AUTOSAR XML (schema 00044)
package /E40_Platform_System_SystemPackage/Components
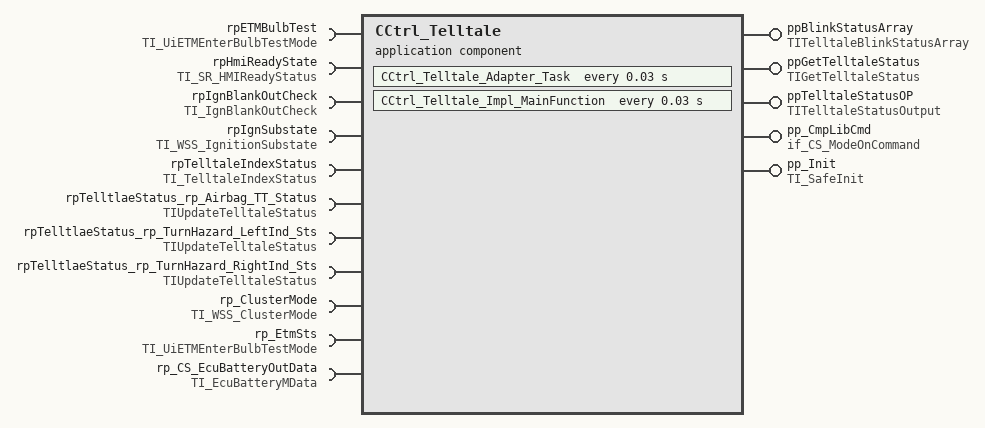
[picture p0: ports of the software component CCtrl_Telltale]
  application sw component type CCtrl_Telltale
    5 x provide port:
      ppBlinkStatusArray: provided-interface=TITelltaleBlinkStatusArray
        provided-com-specs:
          data-element=TTBlinkStatusArray, init-value=constant-reference=CCtrl_TelltaleTTBlinkStatusArrayValue0
          data-element=TTdummyDataForTypes, init-value=constant-reference=CCtrl_TelltaleTTdummyDataForTypesValue0
      ppGetTelltaleStatus: nonqueued-sender-com-spec{data-element=TelltaleFunctionalOpStatus, init-value=constant-reference=CCtrl_TelltaleTelltaleFunctionalOpStatusValue0}, provided-interface=TIGetTelltaleStatus
      ppTelltaleStatusOP: nonqueued-sender-com-spec{data-element=TelltaleOpArray, init-value=constant-reference=CCtrl_TelltaleTelltaleOpArrayValue0}, provided-interface=TITelltaleStatusOutput
      pp_CmpLibCmd: server-com-spec{operation=Impl_OnCommand, queue-length=1}, provided-interface=if_CS_ModeOnCommand
      pp_Init: server-com-spec{operation=Init, queue-length=1}, provided-interface=TI_SafeInit
    11 x require port:
      rpETMBulbTest: nonqueued-receiver-com-spec{data-element=CurrentBulbTestStatus, init-value=constant-reference=CCtrl_TelltaleCurrentBulbTestStatusValue0}, required-interface=TI_UiETMEnterBulbTestMode
      rpHmiReadyState: nonqueued-receiver-com-spec{data-element=HMI_ReadyStatus, init-value=constant-reference=CCtrl_TelltaleHMI_ReadyStatusValue0}, required-interface=TI_SR_HMIReadyStatus
      rpIgnBlankOutCheck: nonqueued-receiver-com-spec{data-element=IgnBlankOutCheck, init-value=constant-reference=CCtrl_TelltaleIgnBlankOutCheckValue0}, required-interface=TI_IgnBlankOutCheck
      rpIgnSubstate: nonqueued-receiver-com-spec{data-element=IgnitionSubstate, init-value=constant-reference=CCtrl_TelltaleIgnitionSubstateValue0}, required-interface=TI_WSS_IgnitionSubstate
      rpTelltaleIndexStatus: required-interface=TI_TelltaleIndexStatus
        required-com-specs:
          data-element=TTIndex, init-value=constant-reference=CCtrl_TelltaleTTIndexValue0
          data-element=TTStatus, init-value=constant-reference=CCtrl_TelltaleTTStatusValue0
      rpTelltlaeStatus_rp_Airbag_TT_Status: nonqueued-receiver-com-spec{data-element=CurrentTelltaleStatus, init-value=constant-reference=CCtrl_TelltaleCurrentTelltaleStatusValue0}, required-interface=TIUpdateTelltaleStatus
      rpTelltlaeStatus_rp_TurnHazard_LeftInd_Sts: nonqueued-receiver-com-spec{data-element=CurrentTelltaleStatus, init-value=constant-reference=CCtrl_TelltaleCurrentTelltaleStatusValue0}, required-interface=TIUpdateTelltaleStatus
      rpTelltlaeStatus_rp_TurnHazard_RightInd_Sts: nonqueued-receiver-com-spec{data-element=CurrentTelltaleStatus, init-value=constant-reference=CCtrl_TelltaleCurrentTelltaleStatusValue0}, required-interface=TIUpdateTelltaleStatus
      rp_ClusterMode: nonqueued-receiver-com-spec{data-element=WSSCurrentClusterMode, init-value=constant-reference=CCtrl_TelltaleWSSCurrentClusterModeValue0}, required-interface=TI_WSS_ClusterMode
      rp_EtmSts: nonqueued-receiver-com-spec{data-element=CurrentBulbTestStatus, init-value=constant-reference=CCtrl_TelltaleCurrentBulbTestStatusValue0}, required-interface=TI_UiETMEnterBulbTestMode
      rp_CS_EcuBatteryOutData: required-com-specs=[EcuBatteryM_GetChannelStatus, EcuBatteryM_GetDIOStatus], required-interface=TI_EcuBatteryMData
    behavior IB_CCtrl_Telltale
      timing event TECCtrl_Telltale_Adapter_Task: start-on-event=CCtrl_Telltale_Adapter_Task, period=0.03
      timing event TECCtrl_Telltale_Impl_MainFunction: start-on-event=CCtrl_Telltale_Impl_MainFunction, period=0.03
      operation invoked event OIE_pp_CmpLibCmd_CCtrl_Telltale_Impl_OnCommandTrigByImpl_OnCommand: start-on-event=CCtrl_Telltale_Impl_OnCommand, operation=pp_CmpLibCmd.Impl_OnCommand
      operation invoked event OIE_pp_Init_CCtrl_Telltale_InitTrigByInit: start-on-event=CCtrl_Telltale_Init, operation=pp_Init.Init
      port-api-options:
        enable-take-address=false, indirect-api=false, port=ppBlinkStatusArray
        enable-take-address=false, indirect-api=false, port=ppGetTelltaleStatus
        enable-take-address=false, indirect-api=false, port=ppTelltaleStatusOP
        enable-take-address=false, indirect-api=false, port=pp_CmpLibCmd
        enable-take-address=false, indirect-api=false, port=pp_Init
        enable-take-address=false, indirect-api=false, port=rpETMBulbTest
        enable-take-address=false, indirect-api=false, port=rpHmiReadyState
        enable-take-address=false, indirect-api=false, port=rpIgnBlankOutCheck
        enable-take-address=false, indirect-api=false, port=rpIgnSubstate
        enable-take-address=false, indirect-api=false, port=rpTelltaleIndexStatus
        enable-take-address=false, indirect-api=false, port=rpTelltlaeStatus_rp_Airbag_TT_Status
        enable-take-address=false, indirect-api=false, port=rpTelltlaeStatus_rp_TurnHazard_LeftInd_Sts
        enable-take-address=false, indirect-api=false, port=rpTelltlaeStatus_rp_TurnHazard_RightInd_Sts
        enable-take-address=false, indirect-api=false, port=rp_ClusterMode
        enable-take-address=false, indirect-api=false, port=rp_EtmSts
        enable-take-address=false, indirect-api=false, port=rp_CS_EcuBatteryOutData
      4 x runnable, all with can-be-invoked-concurrently=true:
        CCtrl_Telltale_Adapter_Task
          data-receive-point-by-arguments:
            11 x access:
              DRA_rpETMBulbTest_CurrentBulbTestStatus: accessed-variable=rpETMBulbTest.CurrentBulbTestStatus
              DRA_rpHmiReadyState_HMI_ReadyStatus: accessed-variable=rpHmiReadyState.HMI_ReadyStatus
              DRA_rpIgnBlankOutCheck_IgnBlankOutCheck: accessed-variable=rpIgnBlankOutCheck.IgnBlankOutCheck
              DRA_rpIgnSubstate_IgnitionSubstate: accessed-variable=rpIgnSubstate.IgnitionSubstate
              DRA_rpTelltaleIndexStatus_TTIndex: accessed-variable=rpTelltaleIndexStatus.TTIndex
              DRA_rpTelltaleIndexStatus_TTStatus: accessed-variable=rpTelltaleIndexStatus.TTStatus
              DRA_rpTelltlaeStatus_rp_Airbag_TT_Status_CurrentTelltaleStatus: accessed-variable=rpTelltlaeStatus_rp_Airbag_TT_Status.CurrentTelltaleStatus
              DRA_rpTelltlaeStatus_rp_TurnHazard_LeftInd_Sts_CurrentTelltaleStatus: accessed-variable=rpTelltlaeStatus_rp_TurnHazard_LeftInd_Sts.CurrentTelltaleStatus
              DRA_rpTelltlaeStatus_rp_TurnHazard_RightInd_Sts_CurrentTelltaleStatus: accessed-variable=rpTelltlaeStatus_rp_TurnHazard_RightInd_Sts.CurrentTelltaleStatus
              DRA_rp_ClusterMode_WSSCurrentClusterMode: accessed-variable=rp_ClusterMode.WSSCurrentClusterMode
              DRA_rp_EtmSts_CurrentBulbTestStatus: accessed-variable=rp_EtmSts.CurrentBulbTestStatus
          data-send-points:
            4 x access:
              DWA_ppBlinkStatusArray_TTBlinkStatusArray: accessed-variable=ppBlinkStatusArray.TTBlinkStatusArray
              DWA_ppBlinkStatusArray_TTdummyDataForTypes: accessed-variable=ppBlinkStatusArray.TTdummyDataForTypes
              DWA_ppGetTelltaleStatus_TelltaleFunctionalOpStatus: accessed-variable=ppGetTelltaleStatus.TelltaleFunctionalOpStatus
              DWA_ppTelltaleStatusOP_TelltaleOpArray: accessed-variable=ppTelltaleStatusOP.TelltaleOpArray
          sync call OA_rp_CS_EcuBatteryOutData_EcuBatteryM_GetChannelStatus: operation=rp_CS_EcuBatteryOutData.EcuBatteryM_GetChannelStatus
          sync call OA_rp_CS_EcuBatteryOutData_EcuBatteryM_GetDIOStatus: operation=rp_CS_EcuBatteryOutData.EcuBatteryM_GetDIOStatus
        CCtrl_Telltale_Impl_MainFunction
          data-receive-point-by-arguments:
            11 x access:
              DRA_rpETMBulbTest_CurrentBulbTestStatus: accessed-variable=rpETMBulbTest.CurrentBulbTestStatus
              DRA_rpHmiReadyState_HMI_ReadyStatus: accessed-variable=rpHmiReadyState.HMI_ReadyStatus
              DRA_rpIgnBlankOutCheck_IgnBlankOutCheck: accessed-variable=rpIgnBlankOutCheck.IgnBlankOutCheck
              DRA_rpIgnSubstate_IgnitionSubstate: accessed-variable=rpIgnSubstate.IgnitionSubstate
              DRA_rpTelltaleIndexStatus_TTIndex: accessed-variable=rpTelltaleIndexStatus.TTIndex
              DRA_rpTelltaleIndexStatus_TTStatus: accessed-variable=rpTelltaleIndexStatus.TTStatus
              DRA_rpTelltlaeStatus_rp_Airbag_TT_Status_CurrentTelltaleStatus: accessed-variable=rpTelltlaeStatus_rp_Airbag_TT_Status.CurrentTelltaleStatus
              DRA_rpTelltlaeStatus_rp_TurnHazard_LeftInd_Sts_CurrentTelltaleStatus: accessed-variable=rpTelltlaeStatus_rp_TurnHazard_LeftInd_Sts.CurrentTelltaleStatus
              DRA_rpTelltlaeStatus_rp_TurnHazard_RightInd_Sts_CurrentTelltaleStatus: accessed-variable=rpTelltlaeStatus_rp_TurnHazard_RightInd_Sts.CurrentTelltaleStatus
              DRA_rp_ClusterMode_WSSCurrentClusterMode: accessed-variable=rp_ClusterMode.WSSCurrentClusterMode
              DRA_rp_EtmSts_CurrentBulbTestStatus: accessed-variable=rp_EtmSts.CurrentBulbTestStatus
          data-send-points:
            4 x access:
              DWA_ppBlinkStatusArray_TTBlinkStatusArray: accessed-variable=ppBlinkStatusArray.TTBlinkStatusArray
              DWA_ppBlinkStatusArray_TTdummyDataForTypes: accessed-variable=ppBlinkStatusArray.TTdummyDataForTypes
              DWA_ppGetTelltaleStatus_TelltaleFunctionalOpStatus: accessed-variable=ppGetTelltaleStatus.TelltaleFunctionalOpStatus
              DWA_ppTelltaleStatusOP_TelltaleOpArray: accessed-variable=ppTelltaleStatusOP.TelltaleOpArray
          sync call OA_rp_CS_EcuBatteryOutData_EcuBatteryM_GetChannelStatus: operation=rp_CS_EcuBatteryOutData.EcuBatteryM_GetChannelStatus
          sync call OA_rp_CS_EcuBatteryOutData_EcuBatteryM_GetDIOStatus: operation=rp_CS_EcuBatteryOutData.EcuBatteryM_GetDIOStatus
        CCtrl_Telltale_Impl_OnCommand
        CCtrl_Telltale_Init
  swc implementation IMPL_CCtrl_Telltale: behavior=IB_CCtrl_Telltale
